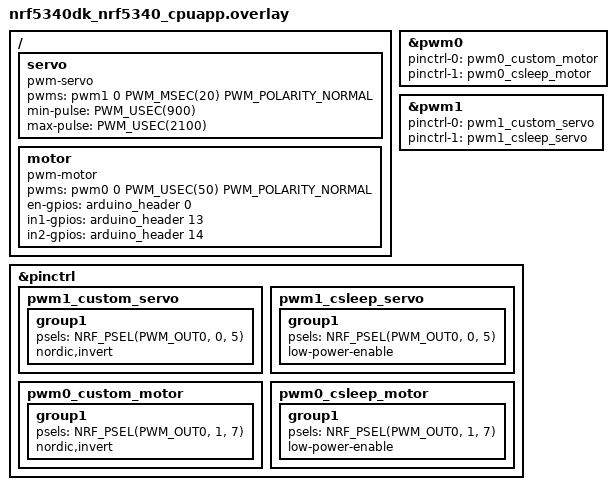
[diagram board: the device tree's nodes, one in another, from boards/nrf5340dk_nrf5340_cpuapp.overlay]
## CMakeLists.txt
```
cmake_minimum_required(VERSION 3.20.0)

find_package(Zephyr REQUIRED HINTS $ENV{ZEPHYR_BASE})
project(test_motor)

target_sources(app PRIVATE src/test_motor.cpp)
```

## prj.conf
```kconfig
CONFIG_ZTEST=y
CONFIG_WALLCKR_MOTION=y
CONFIG_PWM=y
```

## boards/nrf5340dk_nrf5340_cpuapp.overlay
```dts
/ {
    servo: servo {
        compatible = "pwm-servo";
        pwms = <&pwm1 0 PWM_MSEC(20) PWM_POLARITY_NORMAL>;
        min-pulse = <PWM_USEC(900)>;
        max-pulse = <PWM_USEC(2100)>;
    };

    motor: motor {
        compatible = "pwm-motor";
        pwms = <&pwm0 0 PWM_USEC(50) PWM_POLARITY_NORMAL>;
        en-gpios = <&arduino_header 0 GPIO_ACTIVE_HIGH>;
        in1-gpios = <&arduino_header 13 GPIO_ACTIVE_HIGH>;
        in2-gpios = <&arduino_header 14 GPIO_ACTIVE_HIGH>;
    };
};

&pwm0 {
    status = "okay";
    pinctrl-0 = <&pwm0_custom_motor>;
    pinctrl-1 = <&pwm0_csleep_motor>;
    pinctrl-names = "default", "sleep";
};

&pwm1 {
    status = "okay";
    pinctrl-0 = <&pwm1_custom_servo>;
    pinctrl-1 = <&pwm1_csleep_servo>;
    pinctrl-names = "default", "sleep";
};

&pinctrl {
    pwm1_custom_servo: pwm1_custom_servo {
        group1 {
            psels = <NRF_PSEL(PWM_OUT0, 0, 5)>;
            nordic,invert;
        };
    };

    pwm1_csleep_servo: pwm1_csleep_servo {
        group1 {
            psels = <NRF_PSEL(PWM_OUT0, 0, 5)>;
            low-power-enable;
        };
    };

    pwm0_custom_motor: pwm0_custom_motor {
        group1 {
            psels = <NRF_PSEL(PWM_OUT0, 1, 7)>;
            nordic,invert;
        };
    };

    pwm0_csleep_motor: pwm0_csleep_motor {
        group1 {
            psels = <NRF_PSEL(PWM_OUT0, 1, 7)>;
            low-power-enable;
        };
    };

};
```

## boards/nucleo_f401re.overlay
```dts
/ {
    servo: servo {
        compatible = "pwm-servo";
        pwms = <&pwm2 1 PWM_MSEC(20) PWM_POLARITY_NORMAL>;
        min-pulse = <PWM_USEC(900)>;
        max-pulse = <PWM_USEC(2100)>;
    };

    motor: motor {
        compatible = "pwm-motor";
        pwms = <&pwm3 1 PWM_USEC(50) PWM_POLARITY_NORMAL>;
        en-gpios = <&arduino_header 0 GPIO_ACTIVE_HIGH>;
        in1-gpios = <&arduino_header 13 GPIO_ACTIVE_HIGH>;
        in2-gpios = <&arduino_header 14 GPIO_ACTIVE_HIGH>;
    };
};

&pwm2 {
    pinctrl-0 = < &tim2_ch1_pa15 >;
};


&timers3 {
	status = "okay";

	pwm3: pwm {
		status = "okay";
		pinctrl-0 = <&tim3_ch1_pb4>;
		pinctrl-names = "default";
	};
};
```

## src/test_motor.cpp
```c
#include <zephyr/ztest.h>
#include "Motor.h"

ZTEST_SUITE(motor_tests, NULL, NULL, NULL, NULL, NULL);

ZTEST(motor_tests, basic_motor_test)
{
    Motor motor;
    motor.initialize();

    int spd = -100;
    while(true) {
        for(spd = -100; spd <= 100; spd += 5) {
            motor.set_speed(spd);
            k_msleep(1000);
        }

        for(spd = 100; spd >= -100; spd -= 5) {
            motor.set_speed(spd);
            k_msleep(1000);
        }
    }
}
```
